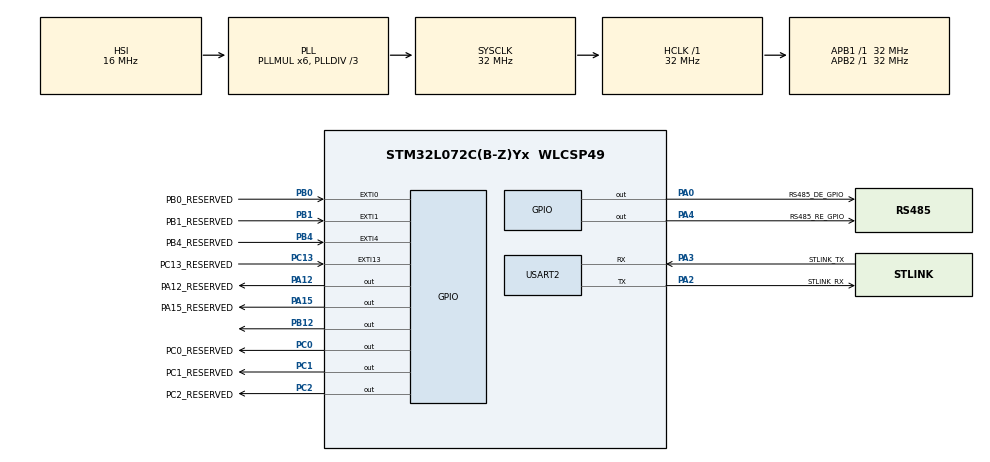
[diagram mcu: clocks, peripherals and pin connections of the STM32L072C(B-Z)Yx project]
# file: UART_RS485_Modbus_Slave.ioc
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Mcu.Family=STM32L0
Mcu.Name=STM32L072C(B-Z)Yx
Mcu.Package=WLCSP49
NVIC.EXTI0_1_IRQn=true\:0\:0\:false\:false\:true\:true\:true
NVIC.EXTI4_15_IRQn=true\:0\:0\:false\:false\:true\:true\:true
NVIC.TIM6_DAC_IRQn=true\:0\:0\:false\:false\:true\:true\:true
NVIC.TIM7_IRQn=true\:0\:0\:false\:false\:true\:true\:true
NVIC.USART2_IRQn=true\:0\:0\:false\:false\:true\:true\:true
PA0.GPIO_Label=RS485_DE_GPIO
PA0.GPIO_Speed=GPIO_SPEED_FREQ_HIGH
PA0.Signal=GPIO_Output
PA12.GPIO_Label=PA12_RESERVED
PA12.GPIO_Speed=GPIO_SPEED_FREQ_HIGH
PA12.Signal=GPIO_Output
PA15.GPIO_Label=PA15_RESERVED
PA15.GPIO_Speed=GPIO_SPEED_FREQ_HIGH
PA15.Signal=GPIO_Output
PA2.GPIO_Label=STLINK_RX
PA2.Mode=Asynchronous
PA2.Signal=USART2_TX
PA3.GPIO_Label=STLINK_TX
PA3.Mode=Asynchronous
PA3.Signal=USART2_RX
PA4.GPIO_Label=RS485_RE_GPIO
PA4.GPIO_Speed=GPIO_SPEED_FREQ_HIGH
PA4.Signal=GPIO_Output
PA6.GPIO_Label=PA6_RESERVED
PA6.Signal=SPI1_MISO
PA7.GPIO_Label=PA7_RESERVED
PA7.Signal=SPI1_MOSI
PB0.GPIO_Label=PB0_RESERVED
PB0.Signal=GPXTI0
PB1.GPIO_Label=PB1_RESERVED
PB1.Signal=GPXTI1
PB12.Signal=GPIO_Output
PB3.GPIO_Label=PB3_RESERVED
PB3.Signal=SPI1_SCK
PB4.GPIO_Label=PB4_RESERVED
PB4.Signal=GPXTI4
PC0.GPIO_Label=PC0_RESERVED
PC0.GPIO_Speed=GPIO_SPEED_FREQ_HIGH
PC0.Signal=GPIO_Output
PC1.GPIO_Label=PC1_RESERVED
PC1.GPIO_Speed=GPIO_SPEED_FREQ_HIGH
PC1.Signal=GPIO_Output
PC13.GPIO_Label=PC13_RESERVED
PC13.Signal=GPXTI13
PC2.GPIO_Label=PC2_RESERVED
PC2.GPIO_Speed=GPIO_SPEED_FREQ_HIGH
PC2.Signal=GPIO_Output
PH0-OSC_IN.Signal=RCC_OSC_IN
PH1-OSC_OUT.Signal=RCC_OSC_OUT
ProjectManager.HeapSize=0x200
ProjectManager.StackSize=0x400
ProjectManager.TargetToolchain=STM32CubeIDE
RCC.AHBFreq_Value=32000000
RCC.APB1Freq_Value=32000000
RCC.APB1TimFreq_Value=32000000
RCC.APB2Freq_Value=32000000
RCC.APB2TimFreq_Value=32000000
RCC.HCLKFreq_Value=32000000
RCC.HSE_VALUE=8000000
RCC.HSI16_VALUE=16000000
RCC.HSI48_VALUE=48000000
RCC.HSI_VALUE=16000000
RCC.LSE_VALUE=32768
RCC.MSI_VALUE=2097000
RCC.PLLDIV=RCC_PLLDIV_3
RCC.PLLMUL=RCC_PLLMUL_6
RCC.SYSCLKFreq_VALUE=32000000
RCC.SYSCLKSource=RCC_SYSCLKSOURCE_PLLCLK
RCC.VCOOutputFreq_Value=96000000
TIM6.AutoReloadPreload=TIM_AUTORELOAD_PRELOAD_ENABLE
TIM6.Period=781
TIM6.Prescaler=31
TIM6.TIM_MasterOutputTrigger=TIM_TRGO_ENABLE
TIM7.AutoReloadPreload=TIM_AUTORELOAD_PRELOAD_ENABLE
TIM7.Period=1823
TIM7.Prescaler=31
TIM7.TIM_MasterOutputTrigger=TIM_TRGO_ENABLE
USART2.VirtualMode-Asynchronous=VM_ASYNC
VP_TIM6_VS_ClockSourceINT.Mode=Enable_Timer
VP_TIM7_VS_ClockSourceINT.Mode=Enable_Timer
board=B-L072Z-LRWAN1

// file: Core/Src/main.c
/* USER CODE BEGIN Header */
/**
  ******************************************************************************
  * @file           : main.c
  * @brief          : Main program body
  ******************************************************************************
  * @attention
  *
  * Copyright (c) 2022 STMicroelectronics.
  * All rights reserved.
  *
  * This software is licensed under terms that can be found in the LICENSE file
  * in the root directory of this software component.
  * If no LICENSE file comes with this software, it is provided AS-IS.
  *
  ******************************************************************************
  */
/* USER CODE END Header */
#include "main.h"
#include "tim.h"
#include "usart.h"
#include "gpio.h"

/* USER CODE BEGIN Includes */
#include "Modbus_Slave.h"
/* USER CODE END Includes */

void SystemClock_Config(void);

int main(void)
{

  /* MCU Configuration--------------------------------------------------------*/

  /* Reset of all peripherals, Initializes the Flash interface and the Systick. */
  HAL_Init();

  /* Configure the system clock */
  SystemClock_Config();

  /* Initialize all configured peripherals */
  MX_GPIO_Init();
  MX_USART2_UART_Init();
  MX_TIM7_Init();
  MX_TIM6_Init();

  /* USER CODE BEGIN 2 */
  MB_Init();
  /* USER CODE END 2 */

  /* Infinite loop */
  while (1)
  {

  }
}

void SystemClock_Config(void)
{
  RCC_OscInitTypeDef RCC_OscInitStruct = {0};
  RCC_ClkInitTypeDef RCC_ClkInitStruct = {0};
  RCC_PeriphCLKInitTypeDef PeriphClkInit = {0};

  /** Configure the main internal regulator output voltage
  */
  __HAL_PWR_VOLTAGESCALING_CONFIG(PWR_REGULATOR_VOLTAGE_SCALE1);
  /** Initializes the RCC Oscillators according to the specified parameters
  * in the RCC_OscInitTypeDef structure.
  */
  RCC_OscInitStruct.OscillatorType = RCC_OSCILLATORTYPE_HSI;
  RCC_OscInitStruct.HSIState = RCC_HSI_ON;
  RCC_OscInitStruct.HSICalibrationValue = RCC_HSICALIBRATION_DEFAULT;
  RCC_OscInitStruct.PLL.PLLState = RCC_PLL_ON;
  RCC_OscInitStruct.PLL.PLLSource = RCC_PLLSOURCE_HSI;
  RCC_OscInitStruct.PLL.PLLMUL = RCC_PLLMUL_6;
  RCC_OscInitStruct.PLL.PLLDIV = RCC_PLLDIV_3;
  if (HAL_RCC_OscConfig(&RCC_OscInitStruct) != HAL_OK)
  {
    Error_Handler();
  }
  /** Initializes the CPU, AHB and APB buses clocks
  */
  RCC_ClkInitStruct.ClockType = RCC_CLOCKTYPE_HCLK|RCC_CLOCKTYPE_SYSCLK
                              |RCC_CLOCKTYPE_PCLK1|RCC_CLOCKTYPE_PCLK2;
  RCC_ClkInitStruct.SYSCLKSource = RCC_SYSCLKSOURCE_PLLCLK;
  RCC_ClkInitStruct.AHBCLKDivider = RCC_SYSCLK_DIV1;
  RCC_ClkInitStruct.APB1CLKDivider = RCC_HCLK_DIV1;
  RCC_ClkInitStruct.APB2CLKDivider = RCC_HCLK_DIV1;

  if (HAL_RCC_ClockConfig(&RCC_ClkInitStruct, FLASH_LATENCY_1) != HAL_OK)
  {
    Error_Handler();
  }
  PeriphClkInit.PeriphClockSelection = RCC_PERIPHCLK_USART2;
  PeriphClkInit.Usart2ClockSelection = RCC_USART2CLKSOURCE_PCLK1;
  if (HAL_RCCEx_PeriphCLKConfig(&PeriphClkInit) != HAL_OK)
  {
    Error_Handler();
  }
}

void Error_Handler(void)
{
  __disable_irq();
  while (1)
  {
  }
}
